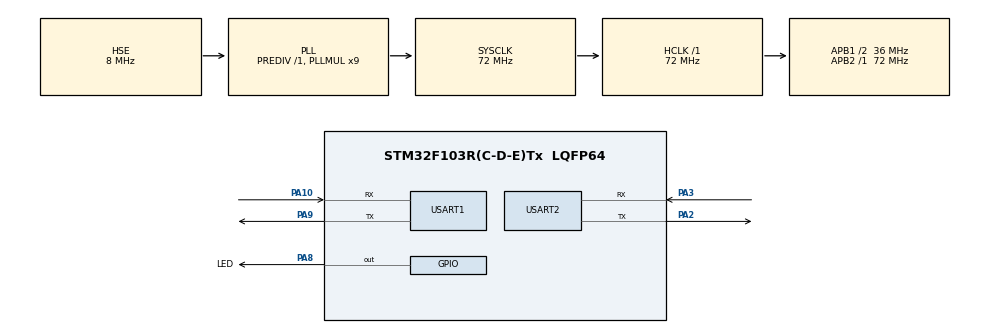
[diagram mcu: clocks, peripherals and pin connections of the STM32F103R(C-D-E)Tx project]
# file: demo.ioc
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Mcu.Family=STM32F1
Mcu.Name=STM32F103R(C-D-E)Tx
Mcu.Package=LQFP64
NVIC.PriorityGroup=NVIC_PRIORITYGROUP_4
NVIC.TIM7_IRQn=true\:15\:0\:false\:false\:true\:false\:true\:true
NVIC.TimeBase=TIM7_IRQn
NVIC.TimeBaseIP=TIM7
NVIC.USART1_IRQn=true\:0\:0\:false\:false\:true\:true\:true\:true
PA10.Mode=Asynchronous
PA10.Signal=USART1_RX
PA13.Mode=Serial_Wire
PA13.Signal=SYS_JTMS-SWDIO
PA14.Mode=Serial_Wire
PA14.Signal=SYS_JTCK-SWCLK
PA2.Mode=Asynchronous
PA2.Signal=USART2_TX
PA3.Mode=Asynchronous
PA3.Signal=USART2_RX
PA8.GPIO_Label=LED
PA8.Signal=GPIO_Output
PA9.Mode=Asynchronous
PA9.Signal=USART1_TX
PD0-OSC_IN.Mode=HSE-External-Oscillator
PD0-OSC_IN.Signal=RCC_OSC_IN
PD1-OSC_OUT.Mode=HSE-External-Oscillator
PD1-OSC_OUT.Signal=RCC_OSC_OUT
ProjectManager.HeapSize=0x200
ProjectManager.StackSize=0x400
ProjectManager.TargetToolchain=MDK-ARM V5
RCC.AHBFreq_Value=72000000
RCC.APB1CLKDivider=RCC_HCLK_DIV2
RCC.APB1Freq_Value=36000000
RCC.APB1TimFreq_Value=72000000
RCC.APB2Freq_Value=72000000
RCC.APB2TimFreq_Value=72000000
RCC.HCLKFreq_Value=72000000
RCC.PLLMUL=RCC_PLL_MUL9
RCC.PLLSourceVirtual=RCC_PLLSOURCE_HSE
RCC.SYSCLKFreq_VALUE=72000000
RCC.SYSCLKSource=RCC_SYSCLKSOURCE_PLLCLK
RCC.USBFreq_Value=72000000
RealThread.RT-Thread.3.1.5.RT_CONSOLEBUF_SIZE=256
RealThread.RT-Thread.3.1.5.RT_DEBUG=1
RealThread.RT-Thread.3.1.5.RT_DEBUG_INIT=1
RealThread.RT-Thread.3.1.5.RT_USING_DEVICE=0
RealThread.RT-Thread.3.1.5.RT_USING_OVERFLOW_CHECK=1
Tencent.TencentOS-tiny.1.0.0.ARMIipackCcTencentOSOotinyJjArchJjCortexIiM3=armcc
Tencent.TencentOS-tiny.1.0.0.ARMIipackCcTencentOSOotinyJjCmsisIiosJjcmsisIios=true
Tencent.TencentOS-tiny.1.0.0.ARMIipackCcTencentOSOotinyJjExampleJjmcuIiit=true
Tencent.TencentOS-tiny.1.0.0.ARMIipackCcTencentOSOotinyJjExampleJjmcuIiplatform=CortexIiM3
Tencent.TencentOS-tiny.1.0.0.ARMIipackCcTencentOSOotinyJjKernelJjcore=true
Tencent.TencentOS-tiny.1.0.0.ARMIipackCcTencentOSOotinyJjKernelJjhal=true
USART1.VirtualMode=VM_ASYNC
USART2.VirtualMode=VM_ASYNC
VP_SYS_VS_tim7.Mode=TIM7
VP_Tencent.TencentOS-tiny_VS_TencentOSOotinyJjARMIipack_1.0.0_1.0.0.Mode=TencentOSOotinyJjARMIipack
board=custom

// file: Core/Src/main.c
/* USER CODE BEGIN Header */
/**
 ******************************************************************************
 * @file           : main.c
 * @brief          : Main program body
 ******************************************************************************
 * @attention
 *
 * Copyright (c) 2023 STMicroelectronics.
 * All rights reserved.
 *
 * This software is licensed under terms that can be found in the LICENSE file
 * in the root directory of this software component.
 * If no LICENSE file comes with this software, it is provided AS-IS.
 *
 ******************************************************************************
 */
/* USER CODE END Header */
#include "main.h"
#include "usart.h"
#include "gpio.h"

/* USER CODE BEGIN Includes */

#include "tos_k.h"
#include "tos_config.h"
#include "mcu_platform_M3.h"

/* USER CODE END Includes */

void SystemClock_Config(void);

/* USER CODE BEGIN 0 */

#define APPLICATION_TASK_STK_SIZE 4096
k_task_t    application_task;
uint8_t     application_task_stk[APPLICATION_TASK_STK_SIZE];
extern void application_entry(void* arg);

/* USER CODE END 0 */

int main(void)
{

    /* MCU Configuration--------------------------------------------------------*/

    /* Reset of all peripherals, Initializes the Flash interface and the Systick. */
    HAL_Init();

    /* Configure the system clock */
    SystemClock_Config();

    /* Initialize all configured peripherals */
    MX_GPIO_Init();
    MX_USART1_UART_Init();
    MX_USART2_UART_Init();
    /* USER CODE BEGIN 2 */
    tos_kprintf("Welcome to TencentOS tiny\r\n");  // printf
    tos_knl_init();                                // TencentOS Tiny kernel initialize
    tos_task_create(&application_task, "application_task", application_entry, NULL, 4, application_task_stk, APPLICATION_TASK_STK_SIZE, 0);
    tos_knl_start();
    /* USER CODE END 2 */

    /* Infinite loop */
    while (1) {

    }
}

void SystemClock_Config(void)
{
    RCC_OscInitTypeDef RCC_OscInitStruct = {0};
    RCC_ClkInitTypeDef RCC_ClkInitStruct = {0};

    /** Initializes the RCC Oscillators according to the specified parameters
     * in the RCC_OscInitTypeDef structure.
     */
    RCC_OscInitStruct.OscillatorType = RCC_OSCILLATORTYPE_HSE;
    RCC_OscInitStruct.HSEState       = RCC_HSE_ON;
    RCC_OscInitStruct.HSEPredivValue = RCC_HSE_PREDIV_DIV1;
    RCC_OscInitStruct.HSIState       = RCC_HSI_ON;
    RCC_OscInitStruct.PLL.PLLState   = RCC_PLL_ON;
    RCC_OscInitStruct.PLL.PLLSource  = RCC_PLLSOURCE_HSE;
    RCC_OscInitStruct.PLL.PLLMUL     = RCC_PLL_MUL9;
    if (HAL_RCC_OscConfig(&RCC_OscInitStruct) != HAL_OK) {
        Error_Handler();
    }

    /** Initializes the CPU, AHB and APB buses clocks
     */
    RCC_ClkInitStruct.ClockType      = RCC_CLOCKTYPE_HCLK | RCC_CLOCKTYPE_SYSCLK | RCC_CLOCKTYPE_PCLK1 | RCC_CLOCKTYPE_PCLK2;
    RCC_ClkInitStruct.SYSCLKSource   = RCC_SYSCLKSOURCE_PLLCLK;
    RCC_ClkInitStruct.AHBCLKDivider  = RCC_SYSCLK_DIV1;
    RCC_ClkInitStruct.APB1CLKDivider = RCC_HCLK_DIV2;
    RCC_ClkInitStruct.APB2CLKDivider = RCC_HCLK_DIV1;

    if (HAL_RCC_ClockConfig(&RCC_ClkInitStruct, FLASH_LATENCY_2) != HAL_OK) {
        Error_Handler();
    }
}

void HAL_TIM_PeriodElapsedCallback(TIM_HandleTypeDef* htim)
{
    if (htim->Instance == TIM7) {
        HAL_IncTick();
    }
}

void Error_Handler(void)
{
    __disable_irq();
    while (1) {
    }
}
